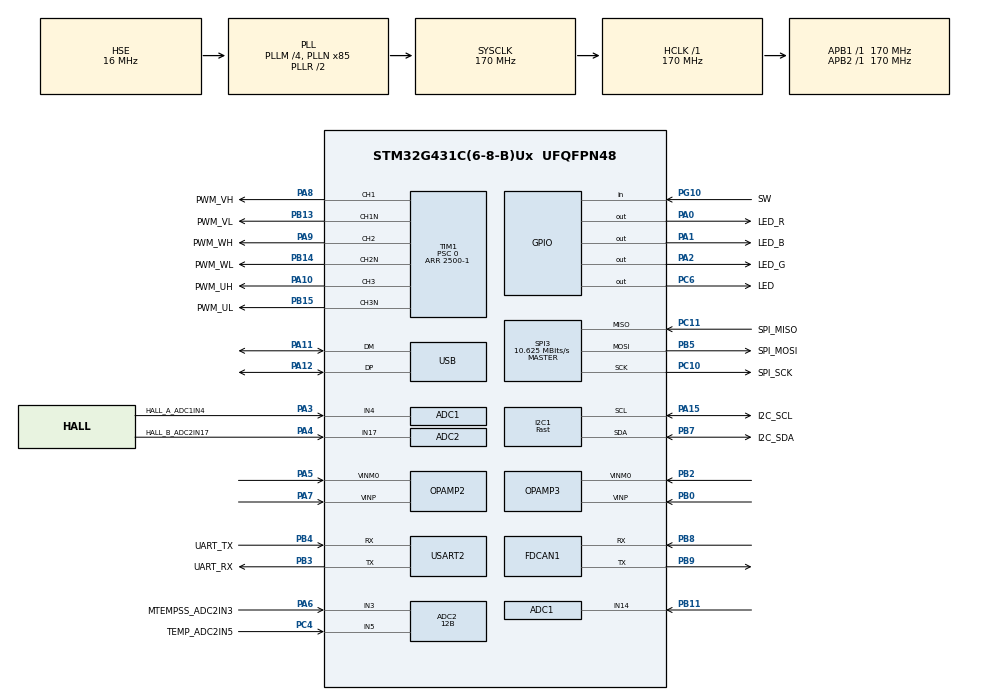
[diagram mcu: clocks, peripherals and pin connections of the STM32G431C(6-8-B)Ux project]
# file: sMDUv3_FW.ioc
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ADC1.EOCSelection=ADC_EOC_SEQ_CONV
ADC1.EnableInjectedConversion=ENABLE
ADC1.EnableRegularConversion=DISABLE
ADC1.ExternalTrigInjecConv=ADC_EXTERNALTRIGINJEC_T1_TRGO
ADC1.InjNumberOfConversion=2
ADC1.InjectedChannel-7\#ChannelInjectedConversion=ADC_CHANNEL_4
ADC1.InjectedChannel-8\#ChannelInjectedConversion=ADC_CHANNEL_14
ADC1.InjectedOffsetNumber-7\#ChannelInjectedConversion=ADC_OFFSET_NONE
ADC1.InjectedOffsetNumber-8\#ChannelInjectedConversion=ADC_OFFSET_NONE
ADC1.InjectedRank-7\#ChannelInjectedConversion=1
ADC1.InjectedRank-8\#ChannelInjectedConversion=2
ADC1.InjectedSamplingTime-7\#ChannelInjectedConversion=ADC_SAMPLETIME_6CYCLES_5
ADC1.InjectedSamplingTime-8\#ChannelInjectedConversion=ADC_SAMPLETIME_12CYCLES_5
ADC1.Rank1_Channel=ADC_CHANNEL_4
ADC1.Rank2_Channel=ADC_CHANNEL_14
ADC1.Rank3_Channel=ADC_CHANNEL_4
ADC1.master=1
ADC2.Channel-11\#ChannelRegularConversion=ADC_CHANNEL_3
ADC2.Channel-12\#ChannelRegularConversion=ADC_CHANNEL_5
ADC2.EOCSelection=ADC_EOC_SEQ_CONV
ADC2.EnableInjectedConversion=ENABLE
ADC2.EnableRegularConversion=ENABLE
ADC2.ExternalTrigInjecConv=ADC_EXTERNALTRIGINJEC_T1_TRGO
ADC2.InjNumberOfConversion=3
ADC2.InjectedChannel-5\#ChannelInjectedConversion=ADC_CHANNEL_VOPAMP2
ADC2.InjectedChannel-8\#ChannelInjectedConversion=ADC_CHANNEL_VOPAMP3_ADC2
ADC2.InjectedChannel-9\#ChannelInjectedConversion=ADC_CHANNEL_17
ADC2.InjectedOffsetNumber-5\#ChannelInjectedConversion=ADC_OFFSET_NONE
ADC2.InjectedOffsetNumber-8\#ChannelInjectedConversion=ADC_OFFSET_NONE
ADC2.InjectedOffsetNumber-9\#ChannelInjectedConversion=ADC_OFFSET_NONE
ADC2.InjectedRank-5\#ChannelInjectedConversion=1
ADC2.InjectedRank-8\#ChannelInjectedConversion=2
ADC2.InjectedRank-9\#ChannelInjectedConversion=3
ADC2.InjectedSamplingTime-5\#ChannelInjectedConversion=ADC_SAMPLETIME_2CYCLES_5
ADC2.InjectedSamplingTime-8\#ChannelInjectedConversion=ADC_SAMPLETIME_2CYCLES_5
ADC2.InjectedSamplingTime-9\#ChannelInjectedConversion=ADC_SAMPLETIME_12CYCLES_5
ADC2.NbrOfConversion=2
ADC2.NbrOfConversionFlag=1
ADC2.OffsetNumber-11\#ChannelRegularConversion=ADC_OFFSET_NONE
ADC2.OffsetNumber-12\#ChannelRegularConversion=ADC_OFFSET_NONE
ADC2.OversamplingMode=DISABLE
ADC2.Rank-11\#ChannelRegularConversion=1
ADC2.Rank-12\#ChannelRegularConversion=2
ADC2.Rank4_Channel=ADC_CHANNEL_3
ADC2.Resolution=ADC_RESOLUTION_12B
ADC2.SamplingTime-11\#ChannelRegularConversion=ADC_SAMPLETIME_12CYCLES_5
ADC2.SamplingTime-12\#ChannelRegularConversion=ADC_SAMPLETIME_12CYCLES_5
Dma.ADC2.0.Direction=DMA_PERIPH_TO_MEMORY
Dma.ADC2.0.EventEnable=DISABLE
Dma.ADC2.0.Instance=DMA1_Channel1
Dma.ADC2.0.MemDataAlignment=DMA_MDATAALIGN_HALFWORD
Dma.ADC2.0.MemInc=DMA_MINC_ENABLE
Dma.ADC2.0.Mode=DMA_CIRCULAR
Dma.ADC2.0.PeriphDataAlignment=DMA_PDATAALIGN_HALFWORD
Dma.ADC2.0.PeriphInc=DMA_PINC_DISABLE
Dma.ADC2.0.Polarity=HAL_DMAMUX_REQ_GEN_RISING
Dma.ADC2.0.Priority=DMA_PRIORITY_LOW
Dma.ADC2.0.RequestNumber=1
Dma.ADC2.0.SignalID=NONE
Dma.ADC2.0.SyncEnable=DISABLE
Dma.ADC2.0.SyncPolarity=HAL_DMAMUX_SYNC_NO_EVENT
Dma.ADC2.0.SyncRequestNumber=1
Dma.ADC2.0.SyncSignalID=NONE
Dma.Request0=ADC2
FDCAN1.AutoRetransmission=ENABLE
FDCAN1.CalculateBaudRateNominal=999999
FDCAN1.CalculateTimeBitNominal=1000
FDCAN1.CalculateTimeQuantumNominal=29.411764705882355
FDCAN1.ClockDivider=FDCAN_CLOCK_DIV1
FDCAN1.ExtFiltersNbr=3
FDCAN1.NominalPrescaler=5
FDCAN1.NominalTimeSeg1=19
FDCAN1.NominalTimeSeg2=14
FDCAN1.StdFiltersNbr=1
FDCAN1.TransmitPause=ENABLE
FDCAN1.TxFifoQueueMode=FDCAN_TX_FIFO_OPERATION
I2C1.I2C_Speed_Mode=I2C_Fast
I2C1.Timing=0x40621236
Mcu.Family=STM32G4
Mcu.Name=STM32G431C(6-8-B)Ux
Mcu.Package=UFQFPN48
NVIC.ADC1_2_IRQn=true\:0\:0\:false\:false\:true\:true\:true\:true
NVIC.DMA1_Channel1_IRQn=true\:0\:0\:false\:false\:true\:false\:true\:true
NVIC.FDCAN1_IT0_IRQn=true\:2\:0\:true\:false\:true\:true\:true\:true
NVIC.FDCAN1_IT1_IRQn=true\:1\:0\:true\:false\:true\:true\:true\:true
NVIC.I2C1_EV_IRQn=true\:2\:0\:true\:false\:true\:true\:true\:true
NVIC.PriorityGroup=NVIC_PRIORITYGROUP_4
NVIC.SPI3_IRQn=true\:2\:0\:true\:false\:true\:true\:true\:true
NVIC.TIM1_TRG_COM_TIM17_IRQn=true\:1\:0\:true\:false\:true\:true\:true\:true
NVIC.USART2_IRQn=true\:2\:0\:true\:false\:true\:true\:true\:true
NVIC.USB_LP_IRQn=true\:0\:0\:false\:false\:true\:false\:true\:true
OPAMP2.PgaGain=OPAMP_PGA_GAIN_16_OR_MINUS_15
OPAMP2.PowerMode=OPAMP_POWERMODE_HIGHSPEED
OPAMP2.SelfCalibration=Enable
OPAMP2.UserTrimming=OPAMP_TRIMMING_USER
OPAMP3.PgaGain=OPAMP_PGA_GAIN_16_OR_MINUS_15
OPAMP3.PowerMode=OPAMP_POWERMODE_HIGHSPEED
OPAMP3.SelfCalibration=Enable
OPAMP3.UserTrimming=OPAMP_TRIMMING_USER
PA0.GPIO_Label=LED_R
PA0.Signal=GPIO_Output
PA1.GPIO_Label=LED_B
PA1.Signal=GPIO_Output
PA10.GPIO_Label=PWM_UH
PA10.Signal=S_TIM1_CH3
PA11.Mode=Device
PA11.Signal=USB_DM
PA12.Mode=Device
PA12.Signal=USB_DP
PA13.Signal=SYS_JTMS-SWDIO
PA14.Signal=SYS_JTCK-SWCLK
PA15.GPIO_Label=I2C_SCL
PA15.Mode=I2C
PA15.Signal=I2C1_SCL
PA2.GPIO_Label=LED_G
PA2.Signal=GPIO_Output
PA3.GPIO_Label=HALL_A_ADC1IN4
PA3.Mode=IN4-Single-Ended
PA3.Signal=ADC1_IN4
PA4.GPIO_Label=HALL_B_ADC2IN17
PA4.Mode=IN17-Single-Ended
PA4.Signal=ADC2_IN17
PA5.Mode=PGA Internally connected_IO0_BIAS
PA5.Signal=OPAMP2_VINM0
PA6.GPIO_Label=MTEMPSS_ADC2IN3
PA6.Mode=IN3-Single-Ended
PA6.Signal=ADC2_IN3
PA7.Mode=PGA Internally connected_IO0_BIAS
PA7.Signal=OPAMP2_VINP
PA8.GPIO_Label=PWM_VH
PA8.Signal=S_TIM1_CH1
PA9.GPIO_Label=PWM_WH
PA9.Signal=S_TIM1_CH2
PB0.Mode=PGA Internally connected_IO0_BIAS
PB0.Signal=OPAMP3_VINP
PB11.Mode=IN14-Single-Ended
PB11.Signal=ADC1_IN14
PB13.GPIO_Label=PWM_VL
PB13.Mode=PWM Generation1 CH1 CH1N
PB13.Signal=TIM1_CH1N
PB14.GPIO_Label=PWM_WL
PB14.Mode=PWM Generation2 CH2 CH2N
PB14.Signal=TIM1_CH2N
PB15.GPIO_Label=PWM_UL
PB15.Mode=PWM Generation3 CH3 CH3N
PB15.Signal=TIM1_CH3N
PB2.Mode=PGA Internally connected_IO0_BIAS
PB2.Signal=OPAMP3_VINM0
PB3.GPIO_Label=UART_RX
PB3.Mode=Asynchronous
PB3.Signal=USART2_TX
PB4.GPIO_Label=UART_TX
PB4.Mode=Asynchronous
PB4.Signal=USART2_RX
PB5.GPIO_Label=SPI_MOSI
PB5.Mode=Full_Duplex_Master
PB5.Signal=SPI3_MOSI
PB7.GPIO_Label=I2C_SDA
PB7.Mode=I2C
PB7.Signal=I2C1_SDA
PB8-BOOT0.Mode=FDCAN_Activate
PB8-BOOT0.Signal=FDCAN1_RX
PB9.Mode=FDCAN_Activate
PB9.Signal=FDCAN1_TX
PC10.GPIO_Label=SPI_SCK
PC10.Mode=Full_Duplex_Master
PC10.Signal=SPI3_SCK
PC11.GPIO_Label=SPI_MISO
PC11.Mode=Full_Duplex_Master
PC11.Signal=SPI3_MISO
PC4.GPIO_Label=TEMP_ADC2IN5
PC4.Mode=IN5-Single-Ended
PC4.Signal=ADC2_IN5
PC6.GPIO_Label=LED
PC6.Signal=GPIO_Output
PF0-OSC_IN.Mode=HSE-External-Oscillator
PF0-OSC_IN.Signal=RCC_OSC_IN
PF1-OSC_OUT.Mode=HSE-External-Oscillator
PF1-OSC_OUT.Signal=RCC_OSC_OUT
PG10-NRST.GPIO_Label=SW
PG10-NRST.GPIO_PuPd=GPIO_PULLUP
PG10-NRST.Signal=GPIO_Input
ProjectManager.HeapSize=0x200
ProjectManager.StackSize=0x400
ProjectManager.TargetToolchain=STM32CubeIDE
RCC.ADC12Freq_Value=170000000
RCC.AHBFreq_Value=170000000
RCC.APB1Freq_Value=170000000
RCC.APB1TimFreq_Value=170000000
RCC.APB2Freq_Value=170000000
RCC.APB2TimFreq_Value=170000000
RCC.CK48CLockSelection=RCC_USBCLKSOURCE_HSI48
RCC.CortexFreq_Value=170000000
RCC.EXTERNAL_CLOCK_VALUE=12288000
RCC.FDCANCLockSelection=RCC_FDCANCLKSOURCE_PLL
RCC.HCLKFreq_Value=170000000
RCC.HSE_VALUE=16000000
RCC.HSI48_VALUE=48000000
RCC.HSI_VALUE=16000000
RCC.LSE_VALUE=32768
RCC.PLLM=RCC_PLLM_DIV4
RCC.PLLN=85
RCC.PLLSourceVirtual=RCC_PLLSOURCE_HSE
RCC.SYSCLKFreq_VALUE=170000000
RCC.SYSCLKSource=RCC_SYSCLKSOURCE_PLLCLK
RCC.USBFreq_Value=48000000
RCC.VCOOutputFreq_Value=340000000
SH.S_TIM1_CH1.0=TIM1_CH1,PWM Generation1 CH1 CH1N
SH.S_TIM1_CH2.0=TIM1_CH2,PWM Generation2 CH2 CH2N
SH.S_TIM1_CH3.0=TIM1_CH3,PWM Generation3 CH3 CH3N
SPI3.BaudRatePrescaler=SPI_BAUDRATEPRESCALER_16
SPI3.CLKPhase=SPI_PHASE_2EDGE
SPI3.CalculateBaudRate=10.625 MBits/s
SPI3.DataSize=SPI_DATASIZE_8BIT
SPI3.Direction=SPI_DIRECTION_2LINES
SPI3.Mode=SPI_MODE_MASTER
SPI3.VirtualType=VM_MASTER
TIM1.AsymmetricalDeadTime=DISABLE
TIM1.Channel-PWM\ Generation1\ CH1\ CH1N=TIM_CHANNEL_1
TIM1.Channel-PWM\ Generation2\ CH2\ CH2N=TIM_CHANNEL_2
TIM1.Channel-PWM\ Generation3\ CH3\ CH3N=TIM_CHANNEL_3
TIM1.CounterMode=TIM_COUNTERMODE_CENTERALIGNED2
TIM1.DeadTime=35
TIM1.OCMode_PWM-PWM\ Generation1\ CH1\ CH1N=TIM_OCMODE_PWM2
TIM1.OCMode_PWM-PWM\ Generation2\ CH2\ CH2N=TIM_OCMODE_PWM2
TIM1.OCMode_PWM-PWM\ Generation3\ CH3\ CH3N=TIM_OCMODE_PWM2
TIM1.OCNPolarity_2=TIM_OCNPOLARITY_HIGH
TIM1.OCNPolarity_3=TIM_OCNPOLARITY_HIGH
TIM1.OCPolarity_2=TIM_OCPOLARITY_HIGH
TIM1.OCPolarity_3=TIM_OCPOLARITY_HIGH
TIM1.PeriodNoDither=2500-1
TIM1.Prescaler=0
TIM1.RepetitionCounter=1
TIM1.TIM_MasterOutputTrigger=TIM_TRGO_UPDATE
TIM1.TIM_MasterOutputTrigger2=TIM_TRGO2_UPDATE
TIM17.PeriodNoDither=1000
TIM17.Prescaler=144-1
USART2.SwapParam=ADVFEATURE_SWAP_ENABLE
USART2.VirtualMode-Asynchronous=VM_ASYNC
USB_DEVICE.CLASS_NAME_FS=CDC
USB_DEVICE.VirtualMode=Cdc
USB_DEVICE.VirtualModeFS=Cdc_FS
VP_ADC2_OPAMP_INTERNAL2.Mode=IN-OPAMP2
VP_ADC2_OPAMP_INTERNAL3.Mode=IN-OPAMP3
VP_CORDIC_VS_CORDIC.Mode=CORDIC_Activate
VP_SYS_VS_DBSignals.Mode=DisableDeadBatterySignals
VP_TIM17_VS_ClockSourceINT.Mode=Enable_Timer
VP_TIM1_VS_ClockSourceINT.Mode=Internal
VP_TIM2_VS_ClockSourceINT.Mode=Internal
VP_USB_DEVICE_VS_USB_DEVICE_CDC_FS.Mode=CDC_FS
board=custom

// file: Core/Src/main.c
/* USER CODE BEGIN Header */
/**
  ******************************************************************************
  * @file           : main.c
  * @brief          : Main program body
  ******************************************************************************
  * @attention
  *
  * Copyright (c) 2024 STMicroelectronics.
  * All rights reserved.
  *
  * This software is licensed under terms that can be found in the LICENSE file
  * in the root directory of this software component.
  * If no LICENSE file comes with this software, it is provided AS-IS.
  *
  ******************************************************************************
  */
/* USER CODE END Header */
#include "main.h"
#include "usb_device.h"

ADC_HandleTypeDef hadc1;
ADC_HandleTypeDef hadc2;
DMA_HandleTypeDef hdma_adc2;

CORDIC_HandleTypeDef hcordic;

FDCAN_HandleTypeDef hfdcan1;

I2C_HandleTypeDef hi2c1;

OPAMP_HandleTypeDef hopamp2;
OPAMP_HandleTypeDef hopamp3;

SPI_HandleTypeDef hspi3;

TIM_HandleTypeDef htim1;
TIM_HandleTypeDef htim2;
TIM_HandleTypeDef htim17;

UART_HandleTypeDef huart2;

void SystemClock_Config(void);
static void MX_GPIO_Init(void);
static void MX_DMA_Init(void);
static void MX_OPAMP2_Init(void);
static void MX_OPAMP3_Init(void);
static void MX_TIM1_Init(void);
static void MX_USART2_UART_Init(void);
static void MX_TIM17_Init(void);
static void MX_ADC1_Init(void);
static void MX_ADC2_Init(void);
static void MX_CORDIC_Init(void);
static void MX_FDCAN1_Init(void);
static void MX_TIM2_Init(void);
static void MX_SPI3_Init(void);
static void MX_I2C1_Init(void);

/* USER CODE BEGIN 0 */

//ソフトウェアリセット時に不安定になるため起動時にヒープをクリア
extern uint32_t _end;    // リンカスクリプトで定義されたヒープ開始アドレス
extern uint32_t _estack; // RAMの終端

void clear_heap(void) {
    uint32_t *heap_start = &_end;
    uint32_t *heap_limit = (uint32_t *)__get_MSP(); // 現在のスタックポインタまで

    // ヒープ領域を0x00で埋める
    // ※スタックを壊さないよう、現在のMSPの手前までをクリアする
    if (heap_start < heap_limit) {
        memset(heap_start, 0, (size_t)heap_limit - (size_t)heap_start);
    }
}

/* USER CODE END 0 */

int main(void)
{

  /* USER CODE BEGIN 1 */
  clear_heap();
  /* USER CODE END 1 */

  /* MCU Configuration--------------------------------------------------------*/

  /* Reset of all peripherals, Initializes the Flash interface and the Systick. */
  HAL_Init();

  /* Configure the system clock */
  SystemClock_Config();

  /* Initialize all configured peripherals */
  MX_GPIO_Init();
  MX_DMA_Init();
  MX_OPAMP2_Init();
  MX_OPAMP3_Init();
  MX_TIM1_Init();
  MX_USART2_UART_Init();
  MX_TIM17_Init();
  MX_ADC1_Init();
  MX_ADC2_Init();
  MX_CORDIC_Init();
  MX_FDCAN1_Init();
  MX_USB_Device_Init();
  MX_TIM2_Init();
  MX_SPI3_Init();
  MX_I2C1_Init();

  /* Infinite loop */
  while (1)
  {

    /* USER CODE BEGIN 3 */
	  cppmain();
  }
  /* USER CODE END 3 */
}

void SystemClock_Config(void)
{
  RCC_OscInitTypeDef RCC_OscInitStruct = {0};
  RCC_ClkInitTypeDef RCC_ClkInitStruct = {0};

  /** Configure the main internal regulator output voltage
  */
  HAL_PWREx_ControlVoltageScaling(PWR_REGULATOR_VOLTAGE_SCALE1_BOOST);

  /** Initializes the RCC Oscillators according to the specified parameters
  * in the RCC_OscInitTypeDef structure.
  */
  RCC_OscInitStruct.OscillatorType = RCC_OSCILLATORTYPE_HSI48|RCC_OSCILLATORTYPE_HSE;
  RCC_OscInitStruct.HSEState = RCC_HSE_ON;
  RCC_OscInitStruct.HSI48State = RCC_HSI48_ON;
  RCC_OscInitStruct.PLL.PLLState = RCC_PLL_ON;
  RCC_OscInitStruct.PLL.PLLSource = RCC_PLLSOURCE_HSE;
  RCC_OscInitStruct.PLL.PLLM = RCC_PLLM_DIV4;
  RCC_OscInitStruct.PLL.PLLN = 85;
  RCC_OscInitStruct.PLL.PLLP = RCC_PLLP_DIV2;
  RCC_OscInitStruct.PLL.PLLQ = RCC_PLLQ_DIV2;
  RCC_OscInitStruct.PLL.PLLR = RCC_PLLR_DIV2;
  if (HAL_RCC_OscConfig(&RCC_OscInitStruct) != HAL_OK)
  {
    Error_Handler();
  }

  /** Initializes the CPU, AHB and APB buses clocks
  */
  RCC_ClkInitStruct.ClockType = RCC_CLOCKTYPE_HCLK|RCC_CLOCKTYPE_SYSCLK
                              |RCC_CLOCKTYPE_PCLK1|RCC_CLOCKTYPE_PCLK2;
  RCC_ClkInitStruct.SYSCLKSource = RCC_SYSCLKSOURCE_PLLCLK;
  RCC_ClkInitStruct.AHBCLKDivider = RCC_SYSCLK_DIV1;
  RCC_ClkInitStruct.APB1CLKDivider = RCC_HCLK_DIV1;
  RCC_ClkInitStruct.APB2CLKDivider = RCC_HCLK_DIV1;

  if (HAL_RCC_ClockConfig(&RCC_ClkInitStruct, FLASH_LATENCY_4) != HAL_OK)
  {
    Error_Handler();
  }
}

static void MX_ADC1_Init(void)
{

  ADC_MultiModeTypeDef multimode = {0};
  ADC_InjectionConfTypeDef sConfigInjected = {0};

  /** Common config
  */
  hadc1.Instance = ADC1;
  hadc1.Init.ClockPrescaler = ADC_CLOCK_SYNC_PCLK_DIV4;
  hadc1.Init.Resolution = ADC_RESOLUTION_12B;
  hadc1.Init.DataAlign = ADC_DATAALIGN_RIGHT;
  hadc1.Init.GainCompensation = 0;
  hadc1.Init.ScanConvMode = ADC_SCAN_ENABLE;
  hadc1.Init.EOCSelection = ADC_EOC_SEQ_CONV;
  hadc1.Init.LowPowerAutoWait = DISABLE;
  hadc1.Init.ContinuousConvMode = DISABLE;
  hadc1.Init.NbrOfConversion = 1;
  hadc1.Init.DiscontinuousConvMode = DISABLE;
  hadc1.Init.DMAContinuousRequests = DISABLE;
  hadc1.Init.Overrun = ADC_OVR_DATA_PRESERVED;
  hadc1.Init.OversamplingMode = DISABLE;
  if (HAL_ADC_Init(&hadc1) != HAL_OK)
  {
    Error_Handler();
  }

  /** Configure the ADC multi-mode
  */
  multimode.Mode = ADC_MODE_INDEPENDENT;
  if (HAL_ADCEx_MultiModeConfigChannel(&hadc1, &multimode) != HAL_OK)
  {
    Error_Handler();
  }

  /** Configure Injected Channel
  */
  sConfigInjected.InjectedChannel = ADC_CHANNEL_4;
  sConfigInjected.InjectedRank = ADC_INJECTED_RANK_1;
  sConfigInjected.InjectedSamplingTime = ADC_SAMPLETIME_6CYCLES_5;
  sConfigInjected.InjectedSingleDiff = ADC_SINGLE_ENDED;
  sConfigInjected.InjectedOffsetNumber = ADC_OFFSET_NONE;
  sConfigInjected.InjectedOffset = 0;
  sConfigInjected.InjectedNbrOfConversion = 2;
  sConfigInjected.InjectedDiscontinuousConvMode = DISABLE;
  sConfigInjected.AutoInjectedConv = DISABLE;
  sConfigInjected.QueueInjectedContext = DISABLE;
  sConfigInjected.ExternalTrigInjecConv = ADC_EXTERNALTRIGINJEC_T1_TRGO;
  sConfigInjected.ExternalTrigInjecConvEdge = ADC_EXTERNALTRIGINJECCONV_EDGE_RISING;
  sConfigInjected.InjecOversamplingMode = DISABLE;
  if (HAL_ADCEx_InjectedConfigChannel(&hadc1, &sConfigInjected) != HAL_OK)
  {
    Error_Handler();
  }

  /** Configure Injected Channel
  */
  sConfigInjected.InjectedChannel = ADC_CHANNEL_14;
  sConfigInjected.InjectedRank = ADC_INJECTED_RANK_2;
  sConfigInjected.InjectedSamplingTime = ADC_SAMPLETIME_12CYCLES_5;
  if (HAL_ADCEx_InjectedConfigChannel(&hadc1, &sConfigInjected) != HAL_OK)
  {
    Error_Handler();
  }

}

static void MX_ADC2_Init(void)
{

  ADC_InjectionConfTypeDef sConfigInjected = {0};
  ADC_ChannelConfTypeDef sConfig = {0};

  /** Common config
  */
  hadc2.Instance = ADC2;
  hadc2.Init.ClockPrescaler = ADC_CLOCK_SYNC_PCLK_DIV4;
  hadc2.Init.Resolution = ADC_RESOLUTION_12B;
  hadc2.Init.DataAlign = ADC_DATAALIGN_RIGHT;
  hadc2.Init.GainCompensation = 0;
  hadc2.Init.ScanConvMode = ADC_SCAN_ENABLE;
  hadc2.Init.EOCSelection = ADC_EOC_SEQ_CONV;
  hadc2.Init.LowPowerAutoWait = DISABLE;
  hadc2.Init.ContinuousConvMode = DISABLE;
  hadc2.Init.NbrOfConversion = 2;
  hadc2.Init.DiscontinuousConvMode = DISABLE;
  hadc2.Init.ExternalTrigConv = ADC_SOFTWARE_START;
  hadc2.Init.ExternalTrigConvEdge = ADC_EXTERNALTRIGCONVEDGE_NONE;
  hadc2.Init.DMAContinuousRequests = DISABLE;
  hadc2.Init.Overrun = ADC_OVR_DATA_PRESERVED;
  hadc2.Init.OversamplingMode = DISABLE;
  if (HAL_ADC_Init(&hadc2) != HAL_OK)
  {
    Error_Handler();
  }

  /** Configure Injected Channel
  */
  sConfigInjected.InjectedChannel = ADC_CHANNEL_VOPAMP2;
  sConfigInjected.InjectedRank = ADC_INJECTED_RANK_1;
  sConfigInjected.InjectedSamplingTime = ADC_SAMPLETIME_2CYCLES_5;
  sConfigInjected.InjectedSingleDiff = ADC_SINGLE_ENDED;
  sConfigInjected.InjectedOffsetNumber = ADC_OFFSET_NONE;
  sConfigInjected.InjectedOffset = 0;
  sConfigInjected.InjectedNbrOfConversion = 3;
  sConfigInjected.InjectedDiscontinuousConvMode = DISABLE;
  sConfigInjected.AutoInjectedConv = DISABLE;
  sConfigInjected.QueueInjectedContext = DISABLE;
  sConfigInjected.ExternalTrigInjecConv = ADC_EXTERNALTRIGINJEC_T1_TRGO;
  sConfigInjected.ExternalTrigInjecConvEdge = ADC_EXTERNALTRIGINJECCONV_EDGE_RISING;
  sConfigInjected.InjecOversamplingMode = DISABLE;
  if (HAL_ADCEx_InjectedConfigChannel(&hadc2, &sConfigInjected) != HAL_OK)
  {
    Error_Handler();
  }

  /** Configure Injected Channel
  */
  sConfigInjected.InjectedChannel = ADC_CHANNEL_VOPAMP3_ADC2;
  sConfigInjected.InjectedRank = ADC_INJECTED_RANK_2;
  if (HAL_ADCEx_InjectedConfigChannel(&hadc2, &sConfigInjected) != HAL_OK)
  {
    Error_Handler();
  }

  /** Configure Injected Channel
  */
  sConfigInjected.InjectedChannel = ADC_CHANNEL_17;
  sConfigInjected.InjectedRank = ADC_INJECTED_RANK_3;
  sConfigInjected.InjectedSamplingTime = ADC_SAMPLETIME_12CYCLES_5;
  if (HAL_ADCEx_InjectedConfigChannel(&hadc2, &sConfigInjected) != HAL_OK)
  {
    Error_Handler();
  }

  /** Configure Regular Channel
  */
  sConfig.Channel = ADC_CHANNEL_3;
  sConfig.Rank = ADC_REGULAR_RANK_1;
  sConfig.SamplingTime = ADC_SAMPLETIME_12CYCLES_5;
  sConfig.SingleDiff = ADC_SINGLE_ENDED;
  sConfig.OffsetNumber = ADC_OFFSET_NONE;
  sConfig.Offset = 0;
  if (HAL_ADC_ConfigChannel(&hadc2, &sConfig) != HAL_OK)
  {
    Error_Handler();
  }

  /** Configure Regular Channel
  */
  sConfig.Channel = ADC_CHANNEL_5;
  sConfig.Rank = ADC_REGULAR_RANK_2;
  if (HAL_ADC_ConfigChannel(&hadc2, &sConfig) != HAL_OK)
  {
    Error_Handler();
  }

}

static void MX_CORDIC_Init(void)
{

  hcordic.Instance = CORDIC;
  if (HAL_CORDIC_Init(&hcordic) != HAL_OK)
  {
    Error_Handler();
  }

}

static void MX_FDCAN1_Init(void)
{

  hfdcan1.Instance = FDCAN1;
  hfdcan1.Init.ClockDivider = FDCAN_CLOCK_DIV1;
  hfdcan1.Init.FrameFormat = FDCAN_FRAME_CLASSIC;
  hfdcan1.Init.Mode = FDCAN_MODE_NORMAL;
  hfdcan1.Init.AutoRetransmission = ENABLE;
  hfdcan1.Init.TransmitPause = ENABLE;
  hfdcan1.Init.ProtocolException = DISABLE;
  hfdcan1.Init.NominalPrescaler = 5;
  hfdcan1.Init.NominalSyncJumpWidth = 1;
  hfdcan1.Init.NominalTimeSeg1 = 19;
  hfdcan1.Init.NominalTimeSeg2 = 14;
  hfdcan1.Init.DataPrescaler = 1;
  hfdcan1.Init.DataSyncJumpWidth = 1;
  hfdcan1.Init.DataTimeSeg1 = 1;
  hfdcan1.Init.DataTimeSeg2 = 1;
  hfdcan1.Init.StdFiltersNbr = 1;
  hfdcan1.Init.ExtFiltersNbr = 3;
  hfdcan1.Init.TxFifoQueueMode = FDCAN_TX_FIFO_OPERATION;
  if (HAL_FDCAN_Init(&hfdcan1) != HAL_OK)
  {
    Error_Handler();
  }

}

static void MX_I2C1_Init(void)
{

  hi2c1.Instance = I2C1;
  hi2c1.Init.Timing = 0x40621236;
  hi2c1.Init.OwnAddress1 = 0;
  hi2c1.Init.AddressingMode = I2C_ADDRESSINGMODE_7BIT;
  hi2c1.Init.DualAddressMode = I2C_DUALADDRESS_DISABLE;
  hi2c1.Init.OwnAddress2 = 0;
  hi2c1.Init.OwnAddress2Masks = I2C_OA2_NOMASK;
  hi2c1.Init.GeneralCallMode = I2C_GENERALCALL_DISABLE;
  hi2c1.Init.NoStretchMode = I2C_NOSTRETCH_DISABLE;
  if (HAL_I2C_Init(&hi2c1) != HAL_OK)
  {
    Error_Handler();
  }

  /** Configure Analogue filter
  */
  if (HAL_I2CEx_ConfigAnalogFilter(&hi2c1, I2C_ANALOGFILTER_ENABLE) != HAL_OK)
  {
    Error_Handler();
  }

  /** Configure Digital filter
  */
  if (HAL_I2CEx_ConfigDigitalFilter(&hi2c1, 0) != HAL_OK)
  {
    Error_Handler();
  }

}

static void MX_OPAMP2_Init(void)
{

  hopamp2.Instance = OPAMP2;
  hopamp2.Init.PowerMode = OPAMP_POWERMODE_HIGHSPEED;
  hopamp2.Init.Mode = OPAMP_PGA_MODE;
  hopamp2.Init.NonInvertingInput = OPAMP_NONINVERTINGINPUT_IO0;
  hopamp2.Init.InternalOutput = ENABLE;
  hopamp2.Init.TimerControlledMuxmode = OPAMP_TIMERCONTROLLEDMUXMODE_DISABLE;
  hopamp2.Init.PgaConnect = OPAMP_PGA_CONNECT_INVERTINGINPUT_IO0_BIAS;
  hopamp2.Init.PgaGain = OPAMP_PGA_GAIN_16_OR_MINUS_15;
  hopamp2.Init.UserTrimming = OPAMP_TRIMMING_USER;
  if (HAL_OPAMP_Init(&hopamp2) != HAL_OK)
  {
    Error_Handler();
  }
  if (HAL_OPAMP_SelfCalibrate(&hopamp2) != HAL_OK)
  {
    Error_Handler();
  }

}

static void MX_OPAMP3_Init(void)
{

  hopamp3.Instance = OPAMP3;
  hopamp3.Init.PowerMode = OPAMP_POWERMODE_HIGHSPEED;
  hopamp3.Init.Mode = OPAMP_PGA_MODE;
  hopamp3.Init.NonInvertingInput = OPAMP_NONINVERTINGINPUT_IO0;
  hopamp3.Init.InternalOutput = ENABLE;
  hopamp3.Init.TimerControlledMuxmode = OPAMP_TIMERCONTROLLEDMUXMODE_DISABLE;
  hopamp3.Init.PgaConnect = OPAMP_PGA_CONNECT_INVERTINGINPUT_IO0_BIAS;
  hopamp3.Init.PgaGain = OPAMP_PGA_GAIN_16_OR_MINUS_15;
  hopamp3.Init.UserTrimming = OPAMP_TRIMMING_USER;
  if (HAL_OPAMP_Init(&hopamp3) != HAL_OK)
  {
    Error_Handler();
  }
  if (HAL_OPAMP_SelfCalibrate(&hopamp3) != HAL_OK)
  {
    Error_Handler();
  }

}

static void MX_SPI3_Init(void)
{

  /* SPI3 parameter configuration*/
  hspi3.Instance = SPI3;
  hspi3.Init.Mode = SPI_MODE_MASTER;
  hspi3.Init.Direction = SPI_DIRECTION_2LINES;
  hspi3.Init.DataSize = SPI_DATASIZE_8BIT;
  hspi3.Init.CLKPolarity = SPI_POLARITY_LOW;
  hspi3.Init.CLKPhase = SPI_PHASE_2EDGE;
  hspi3.Init.NSS = SPI_NSS_SOFT;
  hspi3.Init.BaudRatePrescaler = SPI_BAUDRATEPRESCALER_16;
  hspi3.Init.FirstBit = SPI_FIRSTBIT_MSB;
  hspi3.Init.TIMode = SPI_TIMODE_DISABLE;
  hspi3.Init.CRCCalculation = SPI_CRCCALCULATION_DISABLE;
  hspi3.Init.CRCPolynomial = 7;
  hspi3.Init.CRCLength = SPI_CRC_LENGTH_DATASIZE;
  hspi3.Init.NSSPMode = SPI_NSS_PULSE_DISABLE;
  if (HAL_SPI_Init(&hspi3) != HAL_OK)
  {
    Error_Handler();
  }

}

static void MX_TIM1_Init(void)
{

  TIM_ClockConfigTypeDef sClockSourceConfig = {0};
  TIM_MasterConfigTypeDef sMasterConfig = {0};
  TIM_OC_InitTypeDef sConfigOC = {0};
  TIM_BreakDeadTimeConfigTypeDef sBreakDeadTimeConfig = {0};

  htim1.Instance = TIM1;
  htim1.Init.Prescaler = 0;
  htim1.Init.CounterMode = TIM_COUNTERMODE_CENTERALIGNED2;
  htim1.Init.Period = 2499;
  htim1.Init.ClockDivision = TIM_CLOCKDIVISION_DIV1;
  htim1.Init.RepetitionCounter = 1;
  htim1.Init.AutoReloadPreload = TIM_AUTORELOAD_PRELOAD_DISABLE;
  if (HAL_TIM_Base_Init(&htim1) != HAL_OK)
  {
    Error_Handler();
  }
  sClockSourceConfig.ClockSource = TIM_CLOCKSOURCE_INTERNAL;
  if (HAL_TIM_ConfigClockSource(&htim1, &sClockSourceConfig) != HAL_OK)
  {
    Error_Handler();
  }
  if (HAL_TIM_PWM_Init(&htim1) != HAL_OK)
  {
    Error_Handler();
  }
  sMasterConfig.MasterOutputTrigger = TIM_TRGO_UPDATE;
  sMasterConfig.MasterOutputTrigger2 = TIM_TRGO2_UPDATE;
  sMasterConfig.MasterSlaveMode = TIM_MASTERSLAVEMODE_DISABLE;
  if (HAL_TIMEx_MasterConfigSynchronization(&htim1, &sMasterConfig) != HAL_OK)
  {
    Error_Handler();
  }
  sConfigOC.OCMode = TIM_OCMODE_PWM2;
  sConfigOC.Pulse = 0;
  sConfigOC.OCPolarity = TIM_OCPOLARITY_HIGH;
  sConfigOC.OCNPolarity = TIM_OCNPOLARITY_HIGH;
  sConfigOC.OCFastMode = TIM_OCFAST_DISABLE;
  sConfigOC.OCIdleState = TIM_OCIDLESTATE_RESET;
  sConfigOC.OCNIdleState = TIM_OCNIDLESTATE_RESET;
  if (HAL_TIM_PWM_ConfigChannel(&htim1, &sConfigOC, TIM_CHANNEL_1) != HAL_OK)
  {
    Error_Handler();
  }
  if (HAL_TIM_PWM_ConfigChannel(&htim1, &sConfigOC, TIM_CHANNEL_2) != HAL_OK)
  {
    Error_Handler();
  }
  if (HAL_TIM_PWM_ConfigChannel(&htim1, &sConfigOC, TIM_CHANNEL_3) != HAL_OK)
  {
    Error_Handler();
  }
  sBreakDeadTimeConfig.OffStateRunMode = TIM_OSSR_DISABLE;
  sBreakDeadTimeConfig.OffStateIDLEMode = TIM_OSSI_DISABLE;
  sBreakDeadTimeConfig.LockLevel = TIM_LOCKLEVEL_OFF;
  sBreakDeadTimeConfig.DeadTime = 35;
  sBreakDeadTimeConfig.BreakState = TIM_BREAK_DISABLE;
  sBreakDeadTimeConfig.BreakPolarity = TIM_BREAKPOLARITY_HIGH;
  sBreakDeadTimeConfig.BreakFilter = 0;
  sBreakDeadTimeConfig.BreakAFMode = TIM_BREAK_AFMODE_INPUT;
  sBreakDeadTimeConfig.Break2State = TIM_BREAK2_DISABLE;
  sBreakDeadTimeConfig.Break2Polarity = TIM_BREAK2POLARITY_HIGH;
  sBreakDeadTimeConfig.Break2Filter = 0;
  sBreakDeadTimeConfig.Break2AFMode = TIM_BREAK_AFMODE_INPUT;
  sBreakDeadTimeConfig.AutomaticOutput = TIM_AUTOMATICOUTPUT_DISABLE;
  if (HAL_TIMEx_ConfigBreakDeadTime(&htim1, &sBreakDeadTimeConfig) != HAL_OK)
  {
    Error_Handler();
  }
  HAL_TIM_MspPostInit(&htim1);

}

static void MX_TIM2_Init(void)
{

  TIM_ClockConfigTypeDef sClockSourceConfig = {0};
  TIM_MasterConfigTypeDef sMasterConfig = {0};

  htim2.Instance = TIM2;
  htim2.Init.Prescaler = 0;
  htim2.Init.CounterMode = TIM_COUNTERMODE_UP;
  htim2.Init.Period = 4294967295;
  htim2.Init.ClockDivision = TIM_CLOCKDIVISION_DIV1;
  htim2.Init.AutoReloadPreload = TIM_AUTORELOAD_PRELOAD_DISABLE;
  if (HAL_TIM_Base_Init(&htim2) != HAL_OK)
  {
    Error_Handler();
  }
  sClockSourceConfig.ClockSource = TIM_CLOCKSOURCE_INTERNAL;
  if (HAL_TIM_ConfigClockSource(&htim2, &sClockSourceConfig) != HAL_OK)
  {
    Error_Handler();
  }
  sMasterConfig.MasterOutputTrigger = TIM_TRGO_RESET;
  sMasterConfig.MasterSlaveMode = TIM_MASTERSLAVEMODE_DISABLE;
  if (HAL_TIMEx_MasterConfigSynchronization(&htim2, &sMasterConfig) != HAL_OK)
  {
    Error_Handler();
  }

}

static void MX_TIM17_Init(void)
{

  htim17.Instance = TIM17;
  htim17.Init.Prescaler = 144-1;
  htim17.Init.CounterMode = TIM_COUNTERMODE_UP;
  htim17.Init.Period = 1000;
  htim17.Init.ClockDivision = TIM_CLOCKDIVISION_DIV1;
  htim17.Init.RepetitionCounter = 0;
  htim17.Init.AutoReloadPreload = TIM_AUTORELOAD_PRELOAD_DISABLE;
  if (HAL_TIM_Base_Init(&htim17) != HAL_OK)
  {
    Error_Handler();
  }

}

static void MX_USART2_UART_Init(void)
{

  huart2.Instance = USART2;
  huart2.Init.BaudRate = 115200;
  huart2.Init.WordLength = UART_WORDLENGTH_8B;
  huart2.Init.StopBits = UART_STOPBITS_1;
  huart2.Init.Parity = UART_PARITY_NONE;
  huart2.Init.Mode = UART_MODE_TX_RX;
  huart2.Init.HwFlowCtl = UART_HWCONTROL_NONE;
  huart2.Init.OverSampling = UART_OVERSAMPLING_16;
  huart2.Init.OneBitSampling = UART_ONE_BIT_SAMPLE_DISABLE;
  huart2.Init.ClockPrescaler = UART_PRESCALER_DIV1;
  huart2.AdvancedInit.AdvFeatureInit = UART_ADVFEATURE_SWAP_INIT;
  huart2.AdvancedInit.Swap = UART_ADVFEATURE_SWAP_ENABLE;
  if (HAL_UART_Init(&huart2) != HAL_OK)
  {
    Error_Handler();
  }
  if (HAL_UARTEx_SetTxFifoThreshold(&huart2, UART_TXFIFO_THRESHOLD_1_8) != HAL_OK)
  {
    Error_Handler();
  }
  if (HAL_UARTEx_SetRxFifoThreshold(&huart2, UART_RXFIFO_THRESHOLD_1_8) != HAL_OK)
  {
    Error_Handler();
  }
  if (HAL_UARTEx_DisableFifoMode(&huart2) != HAL_OK)
  {
    Error_Handler();
  }

}

static void MX_DMA_Init(void)
{

  /* DMA controller clock enable */
  __HAL_RCC_DMAMUX1_CLK_ENABLE();
  __HAL_RCC_DMA1_CLK_ENABLE();

  /* DMA interrupt init */
  /* DMA1_Channel1_IRQn interrupt configuration */
  HAL_NVIC_SetPriority(DMA1_Channel1_IRQn, 0, 0);
  HAL_NVIC_EnableIRQ(DMA1_Channel1_IRQn);

}

static void MX_GPIO_Init(void)
{
  LL_GPIO_InitTypeDef GPIO_InitStruct = {0};

  /* GPIO Ports Clock Enable */
  LL_AHB2_GRP1_EnableClock(LL_AHB2_GRP1_PERIPH_GPIOF);
  LL_AHB2_GRP1_EnableClock(LL_AHB2_GRP1_PERIPH_GPIOG);
  LL_AHB2_GRP1_EnableClock(LL_AHB2_GRP1_PERIPH_GPIOA);
  LL_AHB2_GRP1_EnableClock(LL_AHB2_GRP1_PERIPH_GPIOC);
  LL_AHB2_GRP1_EnableClock(LL_AHB2_GRP1_PERIPH_GPIOB);

  /**/
  LL_GPIO_ResetOutputPin(LED_R_GPIO_Port, LED_R_Pin);

  /**/
  LL_GPIO_ResetOutputPin(LED_B_GPIO_Port, LED_B_Pin);

  /**/
  LL_GPIO_ResetOutputPin(LED_G_GPIO_Port, LED_G_Pin);

  /**/
  LL_GPIO_ResetOutputPin(LED_GPIO_Port, LED_Pin);

  /**/
  GPIO_InitStruct.Pin = SW_Pin;
  GPIO_InitStruct.Mode = LL_GPIO_MODE_INPUT;
  GPIO_InitStruct.Pull = LL_GPIO_PULL_UP;
  LL_GPIO_Init(SW_GPIO_Port, &GPIO_InitStruct);

  /**/
  GPIO_InitStruct.Pin = LED_R_Pin;
  GPIO_InitStruct.Mode = LL_GPIO_MODE_OUTPUT;
  GPIO_InitStruct.Speed = LL_GPIO_SPEED_FREQ_LOW;
  GPIO_InitStruct.OutputType = LL_GPIO_OUTPUT_PUSHPULL;
  GPIO_InitStruct.Pull = LL_GPIO_PULL_NO;
  LL_GPIO_Init(LED_R_GPIO_Port, &GPIO_InitStruct);

  /**/
  GPIO_InitStruct.Pin = LED_B_Pin;
  GPIO_InitStruct.Mode = LL_GPIO_MODE_OUTPUT;
  GPIO_InitStruct.Speed = LL_GPIO_SPEED_FREQ_LOW;
  GPIO_InitStruct.OutputType = LL_GPIO_OUTPUT_PUSHPULL;
  GPIO_InitStruct.Pull = LL_GPIO_PULL_NO;
  LL_GPIO_Init(LED_B_GPIO_Port, &GPIO_InitStruct);

  /**/
  GPIO_InitStruct.Pin = LED_G_Pin;
  GPIO_InitStruct.Mode = LL_GPIO_MODE_OUTPUT;
  GPIO_InitStruct.Speed = LL_GPIO_SPEED_FREQ_LOW;
  GPIO_InitStruct.OutputType = LL_GPIO_OUTPUT_PUSHPULL;
  GPIO_InitStruct.Pull = LL_GPIO_PULL_NO;
  LL_GPIO_Init(LED_G_GPIO_Port, &GPIO_InitStruct);

  /**/
  GPIO_InitStruct.Pin = LED_Pin;
  GPIO_InitStruct.Mode = LL_GPIO_MODE_OUTPUT;
  GPIO_InitStruct.Speed = LL_GPIO_SPEED_FREQ_LOW;
  GPIO_InitStruct.OutputType = LL_GPIO_OUTPUT_PUSHPULL;
  GPIO_InitStruct.Pull = LL_GPIO_PULL_NO;
  LL_GPIO_Init(LED_GPIO_Port, &GPIO_InitStruct);

}

void Error_Handler(void)
{
  __disable_irq();
  while (1)
  {
  }
}
